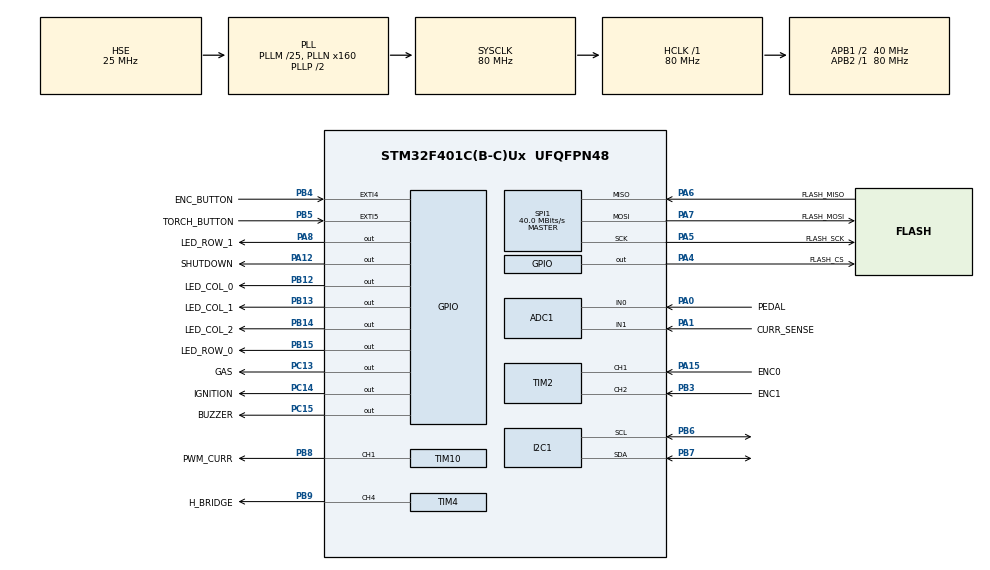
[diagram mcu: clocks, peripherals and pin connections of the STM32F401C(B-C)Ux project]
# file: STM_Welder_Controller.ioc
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ADC1.Channel-0\#ChannelRegularConversion=ADC_CHANNEL_0
ADC1.Channel-1\#ChannelRegularConversion=ADC_CHANNEL_1
ADC1.ClockPrescaler=ADC_CLOCK_SYNC_PCLK_DIV8
ADC1.ContinuousConvMode=ENABLE
ADC1.DMAContinuousRequests=ENABLE
ADC1.NbrOfConversion=2
ADC1.NbrOfConversionFlag=1
ADC1.Rank-0\#ChannelRegularConversion=1
ADC1.Rank-1\#ChannelRegularConversion=2
ADC1.SamplingTime-0\#ChannelRegularConversion=ADC_SAMPLETIME_480CYCLES
ADC1.SamplingTime-1\#ChannelRegularConversion=ADC_SAMPLETIME_480CYCLES
ADC1.ScanConvMode=ENABLE
ADC1.master=1
Dma.ADC1.0.Direction=DMA_PERIPH_TO_MEMORY
Dma.ADC1.0.FIFOMode=DMA_FIFOMODE_DISABLE
Dma.ADC1.0.Instance=DMA2_Stream0
Dma.ADC1.0.MemDataAlignment=DMA_MDATAALIGN_WORD
Dma.ADC1.0.MemInc=DMA_MINC_ENABLE
Dma.ADC1.0.Mode=DMA_CIRCULAR
Dma.ADC1.0.PeriphDataAlignment=DMA_PDATAALIGN_WORD
Dma.ADC1.0.PeriphInc=DMA_PINC_DISABLE
Dma.ADC1.0.Priority=DMA_PRIORITY_LOW
Dma.Request0=ADC1
I2C1.I2C_Mode=I2C_Standard
Mcu.Family=STM32F4
Mcu.Name=STM32F401C(B-C)Ux
Mcu.Package=UFQFPN48
NVIC.DMA2_Stream0_IRQn=true\:0\:0\:false\:false\:true\:false\:true\:true
NVIC.EXTI9_5_IRQn=true\:1\:0\:true\:false\:true\:true\:true\:true
NVIC.PriorityGroup=NVIC_PRIORITYGROUP_4
NVIC.TIM1_TRG_COM_TIM11_IRQn=true\:0\:0\:false\:false\:true\:true\:true\:true
NVIC.TIM1_UP_TIM10_IRQn=true\:0\:0\:false\:false\:true\:true\:true\:true
PA0-WKUP.GPIO_Label=PEDAL
PA0-WKUP.Signal=ADCx_IN0
PA1.GPIO_Label=CURR_SENSE
PA1.Signal=ADCx_IN1
PA12.GPIO_Label=SHUTDOWN
PA12.Signal=GPIO_Output
PA15.GPIO_Label=ENC0
PA15.GPIO_PuPd=GPIO_PULLUP
PA15.Signal=S_TIM2_CH1_ETR
PA4.GPIO_Label=FLASH_CS
PA4.PinState=GPIO_PIN_SET
PA4.Signal=GPIO_Output
PA5.GPIO_Label=FLASH_SCK
PA5.Mode=Full_Duplex_Master
PA5.Signal=SPI1_SCK
PA6.GPIO_Label=FLASH_MISO
PA6.Mode=Full_Duplex_Master
PA6.Signal=SPI1_MISO
PA7.GPIO_Label=FLASH_MOSI
PA7.Mode=Full_Duplex_Master
PA7.Signal=SPI1_MOSI
PA8.GPIO_Label=LED_ROW_1
PA8.Signal=GPIO_Output
PB12.GPIO_Label=LED_COL_0
PB12.Signal=GPIO_Output
PB13.GPIO_Label=LED_COL_1
PB13.Signal=GPIO_Output
PB14.GPIO_Label=LED_COL_2
PB14.Signal=GPIO_Output
PB15.GPIO_Label=LED_ROW_0
PB15.Signal=GPIO_Output
PB3.GPIO_Label=ENC1
PB3.GPIO_PuPd=GPIO_PULLUP
PB3.Signal=S_TIM2_CH2
PB4.GPIO_Label=ENC_BUTTON
PB4.GPIO_ModeDefaultEXTI=GPIO_MODE_IT_FALLING
PB4.GPIO_PuPd=GPIO_PULLUP
PB4.Signal=GPXTI4
PB5.GPIO_Label=TORCH_BUTTON
PB5.GPIO_ModeDefaultEXTI=GPIO_MODE_IT_FALLING
PB5.GPIO_PuPd=GPIO_PULLUP
PB5.Signal=GPXTI5
PB6.Mode=I2C
PB6.Signal=I2C1_SCL
PB7.Mode=I2C
PB7.Signal=I2C1_SDA
PB8.GPIO_Label=PWM_CURR
PB8.Signal=S_TIM10_CH1
PB9.GPIO_Label=H_BRIDGE
PB9.Signal=S_TIM4_CH4
PC13-ANTI_TAMP.GPIO_Label=GAS
PC13-ANTI_TAMP.GPIO_ModeDefaultOutputPP=GPIO_MODE_OUTPUT_PP
PC13-ANTI_TAMP.GPIO_PuPd=GPIO_NOPULL
PC13-ANTI_TAMP.Signal=GPIO_Output
PC14-OSC32_IN.GPIO_Label=IGNITION
PC14-OSC32_IN.GPIO_ModeDefaultOutputPP=GPIO_MODE_OUTPUT_PP
PC14-OSC32_IN.GPIO_PuPd=GPIO_NOPULL
PC14-OSC32_IN.Signal=GPIO_Output
PC15-OSC32_OUT.GPIO_Label=BUZZER
PC15-OSC32_OUT.Signal=GPIO_Output
PH0\ -\ OSC_IN.Mode=HSE-External-Oscillator
PH0\ -\ OSC_IN.Signal=RCC_OSC_IN
PH1\ -\ OSC_OUT.Mode=HSE-External-Oscillator
PH1\ -\ OSC_OUT.Signal=RCC_OSC_OUT
ProjectManager.HeapSize=0x200
ProjectManager.StackSize=0x400
ProjectManager.TargetToolchain=Makefile
RCC.48MHZClocksFreq_Value=40000000
RCC.AHBFreq_Value=80000000
RCC.APB1CLKDivider=RCC_HCLK_DIV2
RCC.APB1Freq_Value=40000000
RCC.APB1TimFreq_Value=80000000
RCC.APB2Freq_Value=80000000
RCC.APB2TimFreq_Value=80000000
RCC.CortexFreq_Value=80000000
RCC.EnbaleCSS=true
RCC.HCLKFreq_Value=80000000
RCC.HSE_VALUE=25000000
RCC.HSI_VALUE=16000000
RCC.LSE_VALUE=32768
RCC.PLLM=25
RCC.PLLN=160
RCC.PLLSourceVirtual=RCC_PLLSOURCE_HSE
RCC.SYSCLKFreq_VALUE=80000000
RCC.SYSCLKSource=RCC_SYSCLKSOURCE_PLLCLK
RCC.VCOOutputFreq_Value=160000000
SH.ADCx_IN0.0=ADC1_IN0,IN0
SH.ADCx_IN1.0=ADC1_IN1,IN1
SH.S_TIM10_CH1.0=TIM10_CH1,PWM Generation1 CH1
SH.S_TIM2_CH1_ETR.0=TIM2_CH1,Encoder_Interface
SH.S_TIM2_CH2.0=TIM2_CH2,Encoder_Interface
SH.S_TIM4_CH4.0=TIM4_CH4,PWM Generation4 CH4
SPI1.CRCCalculation=SPI_CRCCALCULATION_DISABLE
SPI1.CalculateBaudRate=40.0 MBits/s
SPI1.Direction=SPI_DIRECTION_2LINES
SPI1.Mode=SPI_MODE_MASTER
SPI1.VirtualNSS=VM_NSSHARD
SPI1.VirtualType=VM_MASTER
TIM10.AutoReloadPreload=TIM_AUTORELOAD_PRELOAD_ENABLE
TIM10.Channel=TIM_CHANNEL_1
TIM10.OCFastMode_PWM=TIM_OCFAST_ENABLE
TIM10.Period=4200-1
TIM10.Prescaler=0
TIM11.AutoReloadPreload=TIM_AUTORELOAD_PRELOAD_ENABLE
TIM11.Prescaler=32-1
TIM4.AutoReloadPreload=TIM_AUTORELOAD_PRELOAD_ENABLE
TIM4.Channel-PWM\ Generation3\ CH3=TIM_CHANNEL_3
TIM4.Channel-PWM\ Generation4\ CH4=TIM_CHANNEL_4
TIM4.ClockDivision=TIM_CLOCKDIVISION_DIV1
TIM4.Period=999
TIM4.Prescaler=160-1
VP_TIM10_VS_ClockSourceINT.Mode=Enable_Timer
VP_TIM11_VS_ClockSourceINT.Mode=Enable_Timer
VP_TIM4_VS_ClockSourceINT.Mode=Internal
board=custom

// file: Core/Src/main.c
/* USER CODE BEGIN Header */
/**
 ******************************************************************************
 * @file           : main.c
 * @brief          : Main program body
 ******************************************************************************
 * @attention
 *
 * Copyright (c) 2024 STMicroelectronics.
 * All rights reserved.
 *
 * This software is licensed under terms that can be found in the LICENSE file
 * in the root directory of this software component.
 * If no LICENSE file comes with this software, it is provided AS-IS.
 *
 ******************************************************************************
 */
/* USER CODE END Header */
#include "main.h"

/* USER CODE BEGIN Includes */
#include "welder.h"
/* USER CODE END Includes */

ADC_HandleTypeDef hadc1;
DMA_HandleTypeDef hdma_adc1;

I2C_HandleTypeDef hi2c1;

SPI_HandleTypeDef hspi1;

TIM_HandleTypeDef htim2;
TIM_HandleTypeDef htim4;
TIM_HandleTypeDef htim10;
TIM_HandleTypeDef htim11;

void SystemClock_Config(void);
static void MX_GPIO_Init(void);
static void MX_DMA_Init(void);
static void MX_TIM4_Init(void);
static void MX_I2C1_Init(void);
static void MX_ADC1_Init(void);
static void MX_TIM2_Init(void);
static void MX_TIM10_Init(void);
static void MX_TIM11_Init(void);
static void MX_SPI1_Init(void);

int main(void) {

	/* MCU Configuration--------------------------------------------------------*/

	/* Reset of all peripherals, Initializes the Flash interface and the Systick. */
	HAL_Init();

	/* Configure the system clock */
	SystemClock_Config();

	/* Initialize all configured peripherals */
	MX_GPIO_Init();
	MX_DMA_Init();
	MX_TIM4_Init();
	MX_I2C1_Init();
	MX_ADC1_Init();
	MX_TIM2_Init();
	MX_TIM10_Init();
	MX_TIM11_Init();
	MX_SPI1_Init();

	/* Infinite loop */
	/* USER CODE BEGIN WHILE */
	welder();
	while (1) {
		/* USER CODE END WHILE */

	}
}

void SystemClock_Config(void) {
	RCC_OscInitTypeDef RCC_OscInitStruct = {0};
	RCC_ClkInitTypeDef RCC_ClkInitStruct = {0};

	/** Configure the main internal regulator output voltage
	 */
	__HAL_RCC_PWR_CLK_ENABLE();
	__HAL_PWR_VOLTAGESCALING_CONFIG(PWR_REGULATOR_VOLTAGE_SCALE2);

	/** Initializes the RCC Oscillators according to the specified parameters
	 * in the RCC_OscInitTypeDef structure.
	 */
	RCC_OscInitStruct.OscillatorType = RCC_OSCILLATORTYPE_HSE;
	RCC_OscInitStruct.HSEState = RCC_HSE_ON;
	RCC_OscInitStruct.PLL.PLLState = RCC_PLL_ON;
	RCC_OscInitStruct.PLL.PLLSource = RCC_PLLSOURCE_HSE;
	RCC_OscInitStruct.PLL.PLLM = 25;
	RCC_OscInitStruct.PLL.PLLN = 160;
	RCC_OscInitStruct.PLL.PLLP = RCC_PLLP_DIV2;
	RCC_OscInitStruct.PLL.PLLQ = 4;
	if (HAL_RCC_OscConfig(&RCC_OscInitStruct) != HAL_OK) { Error_Handler(); }

	/** Initializes the CPU, AHB and APB buses clocks
	 */
	RCC_ClkInitStruct.ClockType = RCC_CLOCKTYPE_HCLK | RCC_CLOCKTYPE_SYSCLK | RCC_CLOCKTYPE_PCLK1 | RCC_CLOCKTYPE_PCLK2;
	RCC_ClkInitStruct.SYSCLKSource = RCC_SYSCLKSOURCE_PLLCLK;
	RCC_ClkInitStruct.AHBCLKDivider = RCC_SYSCLK_DIV1;
	RCC_ClkInitStruct.APB1CLKDivider = RCC_HCLK_DIV2;
	RCC_ClkInitStruct.APB2CLKDivider = RCC_HCLK_DIV1;

	if (HAL_RCC_ClockConfig(&RCC_ClkInitStruct, FLASH_LATENCY_2) != HAL_OK) { Error_Handler(); }

	/** Enables the Clock Security System
	 */
	HAL_RCC_EnableCSS();
}

static void MX_ADC1_Init(void) {

	ADC_ChannelConfTypeDef sConfig = {0};

	/** Configure the global features of the ADC (Clock, Resolution, Data Alignment and number of conversion)
	 */
	hadc1.Instance = ADC1;
	hadc1.Init.ClockPrescaler = ADC_CLOCK_SYNC_PCLK_DIV8;
	hadc1.Init.Resolution = ADC_RESOLUTION_12B;
	hadc1.Init.ScanConvMode = ENABLE;
	hadc1.Init.ContinuousConvMode = ENABLE;
	hadc1.Init.DiscontinuousConvMode = DISABLE;
	hadc1.Init.ExternalTrigConvEdge = ADC_EXTERNALTRIGCONVEDGE_NONE;
	hadc1.Init.ExternalTrigConv = ADC_SOFTWARE_START;
	hadc1.Init.DataAlign = ADC_DATAALIGN_RIGHT;
	hadc1.Init.NbrOfConversion = 2;
	hadc1.Init.DMAContinuousRequests = ENABLE;
	hadc1.Init.EOCSelection = ADC_EOC_SINGLE_CONV;
	if (HAL_ADC_Init(&hadc1) != HAL_OK) { Error_Handler(); }

	/** Configure for the selected ADC regular channel its corresponding rank in the sequencer and its sample time.
	 */
	sConfig.Channel = ADC_CHANNEL_0;
	sConfig.Rank = 1;
	sConfig.SamplingTime = ADC_SAMPLETIME_480CYCLES;
	if (HAL_ADC_ConfigChannel(&hadc1, &sConfig) != HAL_OK) { Error_Handler(); }

	/** Configure for the selected ADC regular channel its corresponding rank in the sequencer and its sample time.
	 */
	sConfig.Channel = ADC_CHANNEL_1;
	sConfig.Rank = 2;
	if (HAL_ADC_ConfigChannel(&hadc1, &sConfig) != HAL_OK) { Error_Handler(); }
}

static void MX_I2C1_Init(void) {

	hi2c1.Instance = I2C1;
	hi2c1.Init.ClockSpeed = 100000;
	hi2c1.Init.DutyCycle = I2C_DUTYCYCLE_2;
	hi2c1.Init.OwnAddress1 = 0;
	hi2c1.Init.AddressingMode = I2C_ADDRESSINGMODE_7BIT;
	hi2c1.Init.DualAddressMode = I2C_DUALADDRESS_DISABLE;
	hi2c1.Init.OwnAddress2 = 0;
	hi2c1.Init.GeneralCallMode = I2C_GENERALCALL_DISABLE;
	hi2c1.Init.NoStretchMode = I2C_NOSTRETCH_DISABLE;
	if (HAL_I2C_Init(&hi2c1) != HAL_OK) { Error_Handler(); }
}

static void MX_SPI1_Init(void) {

	/* SPI1 parameter configuration*/
	hspi1.Instance = SPI1;
	hspi1.Init.Mode = SPI_MODE_MASTER;
	hspi1.Init.Direction = SPI_DIRECTION_2LINES;
	hspi1.Init.DataSize = SPI_DATASIZE_8BIT;
	hspi1.Init.CLKPolarity = SPI_POLARITY_LOW;
	hspi1.Init.CLKPhase = SPI_PHASE_1EDGE;
	hspi1.Init.NSS = SPI_NSS_SOFT;
	hspi1.Init.BaudRatePrescaler = SPI_BAUDRATEPRESCALER_2;
	hspi1.Init.FirstBit = SPI_FIRSTBIT_MSB;
	hspi1.Init.TIMode = SPI_TIMODE_DISABLE;
	hspi1.Init.CRCCalculation = SPI_CRCCALCULATION_DISABLE;
	hspi1.Init.CRCPolynomial = 10;
	if (HAL_SPI_Init(&hspi1) != HAL_OK) { Error_Handler(); }
}

static void MX_TIM2_Init(void) {

	TIM_Encoder_InitTypeDef sConfig = {0};
	TIM_MasterConfigTypeDef sMasterConfig = {0};

	htim2.Instance = TIM2;
	htim2.Init.Prescaler = 0;
	htim2.Init.CounterMode = TIM_COUNTERMODE_UP;
	htim2.Init.Period = 4294967295;
	htim2.Init.ClockDivision = TIM_CLOCKDIVISION_DIV1;
	htim2.Init.AutoReloadPreload = TIM_AUTORELOAD_PRELOAD_DISABLE;
	sConfig.EncoderMode = TIM_ENCODERMODE_TI1;
	sConfig.IC1Polarity = TIM_ICPOLARITY_RISING;
	sConfig.IC1Selection = TIM_ICSELECTION_DIRECTTI;
	sConfig.IC1Prescaler = TIM_ICPSC_DIV1;
	sConfig.IC1Filter = 0;
	sConfig.IC2Polarity = TIM_ICPOLARITY_RISING;
	sConfig.IC2Selection = TIM_ICSELECTION_DIRECTTI;
	sConfig.IC2Prescaler = TIM_ICPSC_DIV1;
	sConfig.IC2Filter = 0;
	if (HAL_TIM_Encoder_Init(&htim2, &sConfig) != HAL_OK) { Error_Handler(); }
	sMasterConfig.MasterOutputTrigger = TIM_TRGO_RESET;
	sMasterConfig.MasterSlaveMode = TIM_MASTERSLAVEMODE_DISABLE;
	if (HAL_TIMEx_MasterConfigSynchronization(&htim2, &sMasterConfig) != HAL_OK) { Error_Handler(); }
}

static void MX_TIM4_Init(void) {

	TIM_ClockConfigTypeDef sClockSourceConfig = {0};
	TIM_MasterConfigTypeDef sMasterConfig = {0};
	TIM_OC_InitTypeDef sConfigOC = {0};

	htim4.Instance = TIM4;
	htim4.Init.Prescaler = 160 - 1;
	htim4.Init.CounterMode = TIM_COUNTERMODE_UP;
	htim4.Init.Period = 999;
	htim4.Init.ClockDivision = TIM_CLOCKDIVISION_DIV1;
	htim4.Init.AutoReloadPreload = TIM_AUTORELOAD_PRELOAD_ENABLE;
	if (HAL_TIM_Base_Init(&htim4) != HAL_OK) { Error_Handler(); }
	sClockSourceConfig.ClockSource = TIM_CLOCKSOURCE_INTERNAL;
	if (HAL_TIM_ConfigClockSource(&htim4, &sClockSourceConfig) != HAL_OK) { Error_Handler(); }
	if (HAL_TIM_PWM_Init(&htim4) != HAL_OK) { Error_Handler(); }
	sMasterConfig.MasterOutputTrigger = TIM_TRGO_RESET;
	sMasterConfig.MasterSlaveMode = TIM_MASTERSLAVEMODE_DISABLE;
	if (HAL_TIMEx_MasterConfigSynchronization(&htim4, &sMasterConfig) != HAL_OK) { Error_Handler(); }
	sConfigOC.OCMode = TIM_OCMODE_PWM1;
	sConfigOC.Pulse = 0;
	sConfigOC.OCPolarity = TIM_OCPOLARITY_HIGH;
	sConfigOC.OCFastMode = TIM_OCFAST_DISABLE;
	if (HAL_TIM_PWM_ConfigChannel(&htim4, &sConfigOC, TIM_CHANNEL_4) != HAL_OK) { Error_Handler(); }
	HAL_TIM_MspPostInit(&htim4);
}

static void MX_TIM10_Init(void) {

	TIM_OC_InitTypeDef sConfigOC = {0};

	htim10.Instance = TIM10;
	htim10.Init.Prescaler = 0;
	htim10.Init.CounterMode = TIM_COUNTERMODE_UP;
	htim10.Init.Period = 4200 - 1;
	htim10.Init.ClockDivision = TIM_CLOCKDIVISION_DIV1;
	htim10.Init.AutoReloadPreload = TIM_AUTORELOAD_PRELOAD_ENABLE;
	if (HAL_TIM_Base_Init(&htim10) != HAL_OK) { Error_Handler(); }
	if (HAL_TIM_PWM_Init(&htim10) != HAL_OK) { Error_Handler(); }
	sConfigOC.OCMode = TIM_OCMODE_PWM1;
	sConfigOC.Pulse = 0;
	sConfigOC.OCPolarity = TIM_OCPOLARITY_HIGH;
	sConfigOC.OCFastMode = TIM_OCFAST_ENABLE;
	if (HAL_TIM_PWM_ConfigChannel(&htim10, &sConfigOC, TIM_CHANNEL_1) != HAL_OK) { Error_Handler(); }
	HAL_TIM_MspPostInit(&htim10);
}

static void MX_TIM11_Init(void) {

	htim11.Instance = TIM11;
	htim11.Init.Prescaler = 32 - 1;
	htim11.Init.CounterMode = TIM_COUNTERMODE_UP;
	htim11.Init.Period = 65535;
	htim11.Init.ClockDivision = TIM_CLOCKDIVISION_DIV1;
	htim11.Init.AutoReloadPreload = TIM_AUTORELOAD_PRELOAD_ENABLE;
	if (HAL_TIM_Base_Init(&htim11) != HAL_OK) { Error_Handler(); }
}

static void MX_DMA_Init(void) {
	/* DMA controller clock enable */
	__HAL_RCC_DMA2_CLK_ENABLE();

	/* DMA interrupt init */
	/* DMA2_Stream0_IRQn interrupt configuration */
	HAL_NVIC_SetPriority(DMA2_Stream0_IRQn, 0, 0);
	HAL_NVIC_EnableIRQ(DMA2_Stream0_IRQn);
}

static void MX_GPIO_Init(void) {
	GPIO_InitTypeDef GPIO_InitStruct = {0};

	/* GPIO Ports Clock Enable */
	__HAL_RCC_GPIOC_CLK_ENABLE();
	__HAL_RCC_GPIOH_CLK_ENABLE();
	__HAL_RCC_GPIOA_CLK_ENABLE();
	__HAL_RCC_GPIOB_CLK_ENABLE();

	/*Configure GPIO pin Output Level */
	HAL_GPIO_WritePin(GPIOC, GAS_Pin | IGNITION_Pin | BUZZER_Pin, GPIO_PIN_RESET);

	/*Configure GPIO pin Output Level */
	HAL_GPIO_WritePin(FLASH_CS_GPIO_Port, FLASH_CS_Pin, GPIO_PIN_SET);

	/*Configure GPIO pin Output Level */
	HAL_GPIO_WritePin(GPIOB, LED_COL_0_Pin | LED_COL_1_Pin | LED_COL_2_Pin | LED_ROW_0_Pin, GPIO_PIN_RESET);

	/*Configure GPIO pin Output Level */
	HAL_GPIO_WritePin(GPIOA, LED_ROW_1_Pin | SHUTDOWN_Pin, GPIO_PIN_RESET);

	/*Configure GPIO pins : GAS_Pin IGNITION_Pin BUZZER_Pin */
	GPIO_InitStruct.Pin = GAS_Pin | IGNITION_Pin | BUZZER_Pin;
	GPIO_InitStruct.Mode = GPIO_MODE_OUTPUT_PP;
	GPIO_InitStruct.Pull = GPIO_NOPULL;
	GPIO_InitStruct.Speed = GPIO_SPEED_FREQ_LOW;
	HAL_GPIO_Init(GPIOC, &GPIO_InitStruct);

	/*Configure GPIO pins : FLASH_CS_Pin LED_ROW_1_Pin SHUTDOWN_Pin */
	GPIO_InitStruct.Pin = FLASH_CS_Pin | LED_ROW_1_Pin | SHUTDOWN_Pin;
	GPIO_InitStruct.Mode = GPIO_MODE_OUTPUT_PP;
	GPIO_InitStruct.Pull = GPIO_NOPULL;
	GPIO_InitStruct.Speed = GPIO_SPEED_FREQ_LOW;
	HAL_GPIO_Init(GPIOA, &GPIO_InitStruct);

	/*Configure GPIO pins : LED_COL_0_Pin LED_COL_1_Pin LED_COL_2_Pin LED_ROW_0_Pin */
	GPIO_InitStruct.Pin = LED_COL_0_Pin | LED_COL_1_Pin | LED_COL_2_Pin | LED_ROW_0_Pin;
	GPIO_InitStruct.Mode = GPIO_MODE_OUTPUT_PP;
	GPIO_InitStruct.Pull = GPIO_NOPULL;
	GPIO_InitStruct.Speed = GPIO_SPEED_FREQ_LOW;
	HAL_GPIO_Init(GPIOB, &GPIO_InitStruct);

	/*Configure GPIO pins : ENC_BUTTON_Pin TORCH_BUTTON_Pin */
	GPIO_InitStruct.Pin = ENC_BUTTON_Pin | TORCH_BUTTON_Pin;
	GPIO_InitStruct.Mode = GPIO_MODE_IT_FALLING;
	GPIO_InitStruct.Pull = GPIO_PULLUP;
	HAL_GPIO_Init(GPIOB, &GPIO_InitStruct);

	/* EXTI interrupt init*/
	HAL_NVIC_SetPriority(EXTI9_5_IRQn, 1, 0);
	HAL_NVIC_EnableIRQ(EXTI9_5_IRQn);

}

/* USER CODE BEGIN 4 */
void TIM10_IRQHandler(void) {
	HAL_TIM_IRQHandler(&htim10);  // This clears the interrupt flag and calls the callback
}
/* USER CODE END 4 */

void Error_Handler(void) {
	__disable_irq();
	while (1) {}
}
